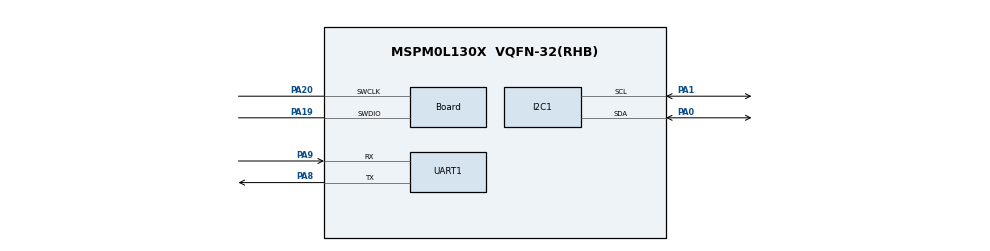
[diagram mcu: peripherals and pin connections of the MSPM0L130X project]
/**
 * @cliArgs --device "MSPM0L130X" --part "Default" --package "VQFN-32(RHB)" --product "mspm0_sdk@2.09.00.00"
 * @versions {"tool":"1.25.0+4268"}
 */

/**
 * Import the modules used in this configuration.
 */
const ADC12  = scripting.addModule("/ti/driverlib/ADC12", {}, false);
const ADC121 = ADC12.addInstance();
const DMA    = scripting.addModule("/ti/driverlib/DMA");
const GPIO   = scripting.addModule("/ti/driverlib/GPIO", {}, false);
const GPIO1  = GPIO.addInstance();
const GPIO2  = GPIO.addInstance();
const GPIO3  = GPIO.addInstance();
const I2C    = scripting.addModule("/ti/driverlib/I2C", {}, false);
const I2C1   = I2C.addInstance();
const TIMER  = scripting.addModule("/ti/driverlib/TIMER", {}, false);
const TIMER1 = TIMER.addInstance();
const UART   = scripting.addModule("/ti/driverlib/UART", {}, false);
const UART1  = UART.addInstance();

/**
 * Write custom configuration values to the imported modules.
 */
ADC121.$name                      = "ADC12_0";
ADC121.powerDownMode              = "DL_ADC12_POWER_DOWN_MODE_MANUAL";
ADC121.sampClkDiv                 = "DL_ADC12_CLOCK_DIVIDE_8";
ADC121.sampClkSrc                 = "DL_ADC12_CLOCK_ULPCLK";
ADC121.samplingOperationMode      = "sequence";
ADC121.endAdd                     = 3;
ADC121.adcMem0chansel             = "DL_ADC12_INPUT_CHAN_2";
ADC121.sampleTime0                = "40 us";
ADC121.enabledInterrupts          = ["DL_ADC12_INTERRUPT_MEM3_RESULT_LOADED"];
ADC121.adcMem1chansel             = "DL_ADC12_INPUT_CHAN_3";
ADC121.adcMem2chansel             = "DL_ADC12_INPUT_CHAN_4";
ADC121.adcMem3chansel             = "DL_ADC12_INPUT_CHAN_5";
ADC121.adcPin2Config.$name        = "ti_driverlib_gpio_GPIOPinGeneric6";
ADC121.adcPin3Config.$name        = "ti_driverlib_gpio_GPIOPinGeneric5";
ADC121.adcPin4Config.$name        = "ti_driverlib_gpio_GPIOPinGeneric7";
ADC121.peripheral.$assign         = "ADC0";
ADC121.peripheral.adcPin2.$assign = "PA25";
ADC121.peripheral.adcPin3.$assign = "PA24/OPA0.IN0-";
ADC121.peripheral.adcPin4.$assign = "PA22";
ADC121.peripheral.adcPin5.$assign = "PA21";
ADC121.adcPin5Config.$name        = "ti_driverlib_gpio_GPIOPinGeneric0";

const Board                       = scripting.addModule("/ti/driverlib/Board", {}, false);
Board.peripheral.$assign          = "DEBUGSS";
Board.peripheral.swclkPin.$assign = "PA20";
Board.peripheral.swdioPin.$assign = "PA19";

GPIO1.$name                          = "GPIO_INT";
GPIO1.associatedPins[0].assignedPort = "PORTA";
GPIO1.associatedPins[0].initialValue = "SET";
GPIO1.associatedPins[0].assignedPin  = "18";
GPIO1.associatedPins[0].$name        = "OUT";

GPIO2.$name                           = "GPIO_BUTTONS";
GPIO2.associatedPins.create(12);
GPIO2.associatedPins[0].direction     = "INPUT";
GPIO2.associatedPins[0].assignedPort  = "PORTA";
GPIO2.associatedPins[0].assignedPin   = "15";
GPIO2.associatedPins[0].interruptEn   = true;
GPIO2.associatedPins[0].polarity      = "RISE_FALL";
GPIO2.associatedPins[0].$name         = "J1_SW";
GPIO2.associatedPins[1].direction     = "INPUT";
GPIO2.associatedPins[1].assignedPort  = "PORTA";
GPIO2.associatedPins[1].assignedPin   = "16";
GPIO2.associatedPins[1].interruptEn   = true;
GPIO2.associatedPins[1].polarity      = "RISE_FALL";
GPIO2.associatedPins[1].$name         = "J2_SW";
GPIO2.associatedPins[2].$name         = "BUT1";
GPIO2.associatedPins[2].direction     = "INPUT";
GPIO2.associatedPins[2].assignedPort  = "PORTA";
GPIO2.associatedPins[2].assignedPin   = "3";
GPIO2.associatedPins[2].interruptEn   = true;
GPIO2.associatedPins[2].polarity      = "RISE_FALL";
GPIO2.associatedPins[3].$name         = "BUT2";
GPIO2.associatedPins[3].direction     = "INPUT";
GPIO2.associatedPins[3].assignedPort  = "PORTA";
GPIO2.associatedPins[3].assignedPin   = "4";
GPIO2.associatedPins[3].interruptEn   = true;
GPIO2.associatedPins[3].polarity      = "RISE_FALL";
GPIO2.associatedPins[4].$name         = "BUT3";
GPIO2.associatedPins[4].direction     = "INPUT";
GPIO2.associatedPins[4].assignedPort  = "PORTA";
GPIO2.associatedPins[4].assignedPin   = "5";
GPIO2.associatedPins[4].interruptEn   = true;
GPIO2.associatedPins[4].polarity      = "RISE_FALL";
GPIO2.associatedPins[5].$name         = "BUT4";
GPIO2.associatedPins[5].direction     = "INPUT";
GPIO2.associatedPins[5].assignedPort  = "PORTA";
GPIO2.associatedPins[5].assignedPin   = "6";
GPIO2.associatedPins[5].interruptEn   = true;
GPIO2.associatedPins[5].polarity      = "RISE_FALL";
GPIO2.associatedPins[6].$name         = "BUT6";
GPIO2.associatedPins[6].direction     = "INPUT";
GPIO2.associatedPins[6].assignedPort  = "PORTA";
GPIO2.associatedPins[6].assignedPin   = "10";
GPIO2.associatedPins[6].interruptEn   = true;
GPIO2.associatedPins[6].polarity      = "RISE_FALL";
GPIO2.associatedPins[7].$name         = "BUT7";
GPIO2.associatedPins[7].direction     = "INPUT";
GPIO2.associatedPins[7].assignedPort  = "PORTA";
GPIO2.associatedPins[7].assignedPin   = "11";
GPIO2.associatedPins[7].interruptEn   = true;
GPIO2.associatedPins[7].polarity      = "RISE_FALL";
GPIO2.associatedPins[8].$name         = "BUT9";
GPIO2.associatedPins[8].direction     = "INPUT";
GPIO2.associatedPins[8].assignedPort  = "PORTA";
GPIO2.associatedPins[8].assignedPin   = "17";
GPIO2.associatedPins[8].interruptEn   = true;
GPIO2.associatedPins[8].polarity      = "RISE_FALL";
GPIO2.associatedPins[9].$name         = "BUT10";
GPIO2.associatedPins[9].direction     = "INPUT";
GPIO2.associatedPins[9].assignedPort  = "PORTA";
GPIO2.associatedPins[9].assignedPin   = "23";
GPIO2.associatedPins[9].interruptEn   = true;
GPIO2.associatedPins[9].polarity      = "RISE_FALL";
GPIO2.associatedPins[10].$name        = "R_BUT1";
GPIO2.associatedPins[10].direction    = "INPUT";
GPIO2.associatedPins[10].assignedPort = "PORTA";
GPIO2.associatedPins[10].assignedPin  = "26";
GPIO2.associatedPins[10].interruptEn  = true;
GPIO2.associatedPins[10].polarity     = "RISE_FALL";
GPIO2.associatedPins[11].$name        = "R_BUT";
GPIO2.associatedPins[11].direction    = "INPUT";
GPIO2.associatedPins[11].assignedPort = "PORTA";
GPIO2.associatedPins[11].assignedPin  = "27";
GPIO2.associatedPins[11].interruptEn  = true;
GPIO2.associatedPins[11].polarity     = "RISE_FALL";

GPIO3.$name                          = "GPIO_LEDS";
GPIO3.associatedPins[0].initialValue = "SET";
GPIO3.associatedPins[0].assignedPort = "PORTA";
GPIO3.associatedPins[0].assignedPin  = "13";
GPIO3.associatedPins[0].$name        = "LED_GREEN";

I2C1.basicControllerBusSpeed           = 400000;
I2C1.advControllerTXFIFOTRIG           = "BYTES_1";
I2C1.basicTargetAddress                = 0x48;
I2C1.$name                             = "I2C";
I2C1.basicEnableTarget                 = true;
I2C1.advTargetTXFIFOTRIG               = "BYTES_1";
I2C1.intTarget                         = ["RXFIFO_TRIGGER","START","STOP"];
I2C1.advAnalogGlitchFilter             = "DISABLED";
I2C1.advTargetTXEmptyEn                = true;
I2C1.peripheral.$assign                = "I2C0";
I2C1.peripheral.sdaPin.$assign         = "PA0";
I2C1.peripheral.sclPin.$assign         = "PA1";
I2C1.sdaPinConfig.$name                = "ti_driverlib_gpio_GPIOPinGeneric1";
I2C1.sdaPinConfig.hideOutputInversion  = scripting.forceWrite(false);
I2C1.sdaPinConfig.onlyInternalResistor = scripting.forceWrite(false);
I2C1.sdaPinConfig.passedPeripheralType = scripting.forceWrite("Digital");
I2C1.sclPinConfig.$name                = "ti_driverlib_gpio_GPIOPinGeneric2";
I2C1.sclPinConfig.hideOutputInversion  = scripting.forceWrite(false);
I2C1.sclPinConfig.onlyInternalResistor = scripting.forceWrite(false);
I2C1.sclPinConfig.passedPeripheralType = scripting.forceWrite("Digital");

const SYSCTL       = scripting.addModule("/ti/driverlib/SYSCTL", {}, false);
SYSCTL.clockTreeEn = true;

TIMER1.$name   = "TIMER_0";
TIMER1.profile = "Basic_Periodic";

UART1.$name                    = "UART_0";
UART1.targetBaudRate           = 115200;
UART1.uartClkDiv               = "8";
UART1.enableFIFO               = true;
UART1.rxFifoThreshold          = "DL_UART_RX_FIFO_LEVEL_ONE_ENTRY";
UART1.txFifoThreshold          = "DL_UART_TX_FIFO_LEVEL_ONE_ENTRY";
UART1.enabledInterrupts        = ["DMA_DONE_TX","EOT_DONE"];
UART1.peripheral.rxPin.$assign = "PA9";
UART1.peripheral.txPin.$assign = "PA8";
UART1.txPinConfig.$name        = "ti_driverlib_gpio_GPIOPinGeneric3";
UART1.rxPinConfig.$name        = "ti_driverlib_gpio_GPIOPinGeneric4";

/**
 * Pinmux solution for unlocked pins/peripherals. This ensures that minor changes to the automatic solver in a future
 * version of the tool will not impact the pinmux you originally saw.  These lines can be completely deleted in order to
 * re-solve from scratch.
 */
GPIO1.associatedPins[0].pin.$suggestSolution  = "PA18";
GPIO2.associatedPins[0].pin.$suggestSolution  = "PA15";
GPIO2.associatedPins[1].pin.$suggestSolution  = "PA16";
GPIO2.associatedPins[2].pin.$suggestSolution  = "PA3";
GPIO2.associatedPins[3].pin.$suggestSolution  = "PA4";
GPIO2.associatedPins[4].pin.$suggestSolution  = "PA5";
GPIO2.associatedPins[5].pin.$suggestSolution  = "PA6";
GPIO2.associatedPins[6].pin.$suggestSolution  = "PA10";
GPIO2.associatedPins[7].pin.$suggestSolution  = "PA11";
GPIO2.associatedPins[8].pin.$suggestSolution  = "PA17/OPA1.IN0-";
GPIO2.associatedPins[9].pin.$suggestSolution  = "PA23";
GPIO2.associatedPins[10].pin.$suggestSolution = "PA26";
GPIO2.associatedPins[11].pin.$suggestSolution = "PA27";
GPIO3.associatedPins[0].pin.$suggestSolution  = "PA13";
TIMER1.peripheral.$suggestSolution            = "TIMG0";
UART1.peripheral.$suggestSolution             = "UART0";
